AUTOSAR XML (schema 4-0-3)
package /Svc_NvM
  4 x impl type:
    NvM_BlockIdType: implementation-data-type=uint16
    NvM_RequestResultType: compu {0=NVM_REQ_OK, 1=NVM_REQ_NOT_OK, 2=NVM_REQ_PENDING, 3=NVM_REQ_INTEGRITY_FAILED, 4=NVM_REQ_BLOCK_SKIPPED, 5=NVM_REQ_NV_INVALIDATED, 6=NVM_REQ_CANCELED, 7=NVM_REQ_REDUNDANCY_FAILED, 8=NVM_REQ_RESTORED_FROM_ROM, 9=NVM_MAXVALUE}, implementation-data-type=uint8
    VoidPtr: category=DATA_REFERENCE, sw-pointer-target-props={target-category=VALUE, base-type=void}
    ConstVoidPtr: category=DATA_REFERENCE, sw-pointer-target-props={target-category=VALUE, base-type=void, sw-impl-policy=CONST}
  client server interface NvMNotifyInitBlock: is-service=true, service-kind=NON-VOLATILE-RAM-MANAGER
    operation InitBlock
  client server interface NvMNotifyJobFinished: is-service=true, service-kind=NON-VOLATILE-RAM-MANAGER
    operation JobFinished
      arg ServiceId: type=uint8, direction=IN
      arg JobResult: type=NvM_RequestResultType, direction=IN
  client server interface NvMService: is-service=true, service-kind=NON-VOLATILE-RAM-MANAGER
    8 x operation, all with possible-error=E_NOT_OK:
      GetErrorStatus
        arg RequestResultPtr: type=NvM_RequestResultType, direction=OUT
      SetRamBlockStatus
        arg BlockChanged: type=boolean, direction=IN
      ReadBlock
        arg Destination: type=VoidPtr, direction=IN
      WriteBlock
        arg Source: type=ConstVoidPtr, direction=IN
      RestoreBlockDefaults
        arg DstPtr: type=VoidPtr, direction=IN
      CancelJobs
      EraseNvBlock
      InvalidateNvBlock
    error E_NOT_OK: error-code=1
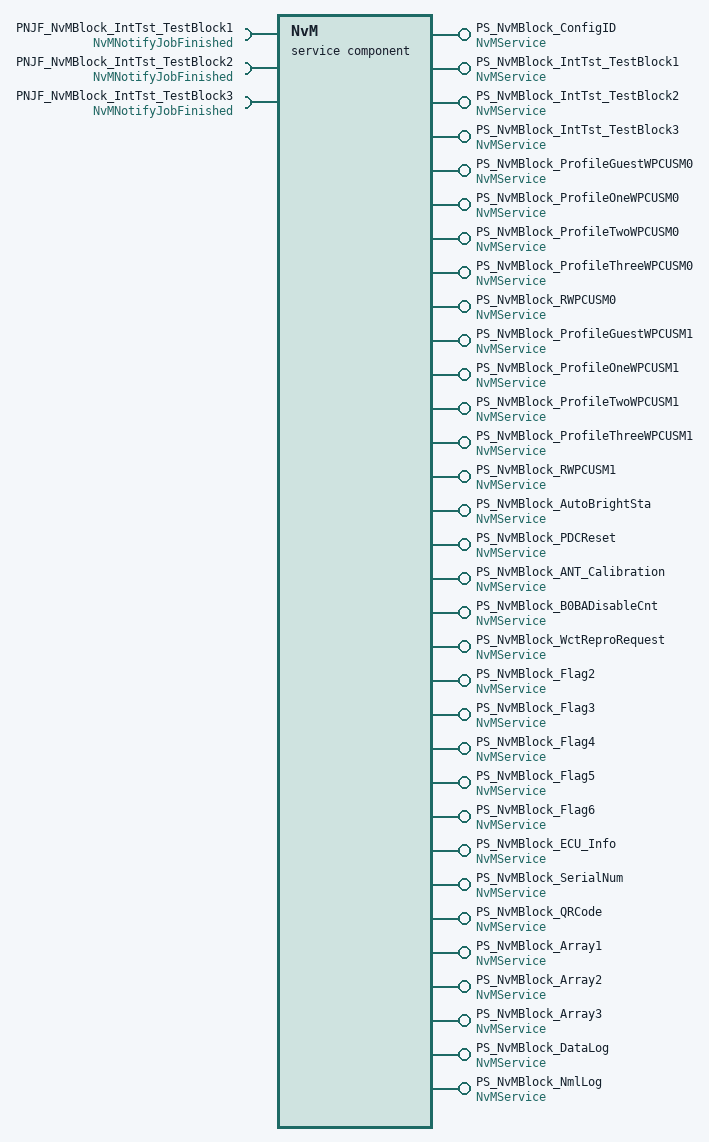
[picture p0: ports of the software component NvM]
  service sw component type NvM
    provide port PS_NvMBlock_ConfigID: provided-interface=NvMService
      provided-com-specs:
        operation=CancelJobs, queue-length=1
        operation=EraseNvBlock, queue-length=1
        operation=GetErrorStatus, queue-length=1
        operation=InvalidateNvBlock, queue-length=1
        operation=ReadBlock, queue-length=1
        operation=RestoreBlockDefaults, queue-length=1
        operation=SetRamBlockStatus, queue-length=1
        operation=WriteBlock, queue-length=1
    provide port PS_NvMBlock_IntTst_TestBlock1: provided-interface=NvMService
      provided-com-specs:
        operation=CancelJobs, queue-length=1
        operation=EraseNvBlock, queue-length=1
        operation=GetErrorStatus, queue-length=1
        operation=InvalidateNvBlock, queue-length=1
        operation=ReadBlock, queue-length=1
        operation=RestoreBlockDefaults, queue-length=1
        operation=SetRamBlockStatus, queue-length=1
        operation=WriteBlock, queue-length=1
    require port PNJF_NvMBlock_IntTst_TestBlock1: client-com-spec=JobFinished, required-interface=NvMNotifyJobFinished
    provide port PS_NvMBlock_IntTst_TestBlock2: provided-interface=NvMService
      provided-com-specs:
        operation=CancelJobs, queue-length=1
        operation=EraseNvBlock, queue-length=1
        operation=GetErrorStatus, queue-length=1
        operation=InvalidateNvBlock, queue-length=1
        operation=ReadBlock, queue-length=1
        operation=RestoreBlockDefaults, queue-length=1
        operation=SetRamBlockStatus, queue-length=1
        operation=WriteBlock, queue-length=1
    require port PNJF_NvMBlock_IntTst_TestBlock2: client-com-spec=JobFinished, required-interface=NvMNotifyJobFinished
    provide port PS_NvMBlock_IntTst_TestBlock3: provided-interface=NvMService
      provided-com-specs:
        operation=CancelJobs, queue-length=1
        operation=EraseNvBlock, queue-length=1
        operation=GetErrorStatus, queue-length=1
        operation=InvalidateNvBlock, queue-length=1
        operation=ReadBlock, queue-length=1
        operation=RestoreBlockDefaults, queue-length=1
        operation=SetRamBlockStatus, queue-length=1
        operation=WriteBlock, queue-length=1
    require port PNJF_NvMBlock_IntTst_TestBlock3: client-com-spec=JobFinished, required-interface=NvMNotifyJobFinished
    28 x provide port, all with provided-interface=NvMService:
      PS_NvMBlock_ProfileGuestWPCUSM0
        provided-com-specs:
          operation=CancelJobs, queue-length=1
          operation=EraseNvBlock, queue-length=1
          operation=GetErrorStatus, queue-length=1
          operation=InvalidateNvBlock, queue-length=1
          operation=ReadBlock, queue-length=1
          operation=RestoreBlockDefaults, queue-length=1
          operation=SetRamBlockStatus, queue-length=1
          operation=WriteBlock, queue-length=1
      PS_NvMBlock_ProfileOneWPCUSM0
        provided-com-specs:
          operation=CancelJobs, queue-length=1
          operation=EraseNvBlock, queue-length=1
          operation=GetErrorStatus, queue-length=1
          operation=InvalidateNvBlock, queue-length=1
          operation=ReadBlock, queue-length=1
          operation=RestoreBlockDefaults, queue-length=1
          operation=SetRamBlockStatus, queue-length=1
          operation=WriteBlock, queue-length=1
      PS_NvMBlock_ProfileTwoWPCUSM0
        provided-com-specs:
          operation=CancelJobs, queue-length=1
          operation=EraseNvBlock, queue-length=1
          operation=GetErrorStatus, queue-length=1
          operation=InvalidateNvBlock, queue-length=1
          operation=ReadBlock, queue-length=1
          operation=RestoreBlockDefaults, queue-length=1
          operation=SetRamBlockStatus, queue-length=1
          operation=WriteBlock, queue-length=1
      PS_NvMBlock_ProfileThreeWPCUSM0
        provided-com-specs:
          operation=CancelJobs, queue-length=1
          operation=EraseNvBlock, queue-length=1
          operation=GetErrorStatus, queue-length=1
          operation=InvalidateNvBlock, queue-length=1
          operation=ReadBlock, queue-length=1
          operation=RestoreBlockDefaults, queue-length=1
          operation=SetRamBlockStatus, queue-length=1
          operation=WriteBlock, queue-length=1
      PS_NvMBlock_RWPCUSM0
        provided-com-specs:
          operation=CancelJobs, queue-length=1
          operation=EraseNvBlock, queue-length=1
          operation=GetErrorStatus, queue-length=1
          operation=InvalidateNvBlock, queue-length=1
          operation=ReadBlock, queue-length=1
          operation=RestoreBlockDefaults, queue-length=1
          operation=SetRamBlockStatus, queue-length=1
          operation=WriteBlock, queue-length=1
      PS_NvMBlock_ProfileGuestWPCUSM1
        provided-com-specs:
          operation=CancelJobs, queue-length=1
          operation=EraseNvBlock, queue-length=1
          operation=GetErrorStatus, queue-length=1
          operation=InvalidateNvBlock, queue-length=1
          operation=ReadBlock, queue-length=1
          operation=RestoreBlockDefaults, queue-length=1
          operation=SetRamBlockStatus, queue-length=1
          operation=WriteBlock, queue-length=1
      PS_NvMBlock_ProfileOneWPCUSM1
        provided-com-specs:
          operation=CancelJobs, queue-length=1
          operation=EraseNvBlock, queue-length=1
          operation=GetErrorStatus, queue-length=1
          operation=InvalidateNvBlock, queue-length=1
          operation=ReadBlock, queue-length=1
          operation=RestoreBlockDefaults, queue-length=1
          operation=SetRamBlockStatus, queue-length=1
          operation=WriteBlock, queue-length=1
      PS_NvMBlock_ProfileTwoWPCUSM1
        provided-com-specs:
          operation=CancelJobs, queue-length=1
          operation=EraseNvBlock, queue-length=1
          operation=GetErrorStatus, queue-length=1
          operation=InvalidateNvBlock, queue-length=1
          operation=ReadBlock, queue-length=1
          operation=RestoreBlockDefaults, queue-length=1
          operation=SetRamBlockStatus, queue-length=1
          operation=WriteBlock, queue-length=1
      PS_NvMBlock_ProfileThreeWPCUSM1
        provided-com-specs:
          operation=CancelJobs, queue-length=1
          operation=EraseNvBlock, queue-length=1
          operation=GetErrorStatus, queue-length=1
          operation=InvalidateNvBlock, queue-length=1
          operation=ReadBlock, queue-length=1
          operation=RestoreBlockDefaults, queue-length=1
          operation=SetRamBlockStatus, queue-length=1
          operation=WriteBlock, queue-length=1
      PS_NvMBlock_RWPCUSM1
        provided-com-specs:
          operation=CancelJobs, queue-length=1
          operation=EraseNvBlock, queue-length=1
          operation=GetErrorStatus, queue-length=1
          operation=InvalidateNvBlock, queue-length=1
          operation=ReadBlock, queue-length=1
          operation=RestoreBlockDefaults, queue-length=1
          operation=SetRamBlockStatus, queue-length=1
          operation=WriteBlock, queue-length=1
      PS_NvMBlock_AutoBrightSta
        provided-com-specs:
          operation=CancelJobs, queue-length=1
          operation=EraseNvBlock, queue-length=1
          operation=GetErrorStatus, queue-length=1
          operation=InvalidateNvBlock, queue-length=1
          operation=ReadBlock, queue-length=1
          operation=RestoreBlockDefaults, queue-length=1
          operation=SetRamBlockStatus, queue-length=1
          operation=WriteBlock, queue-length=1
      PS_NvMBlock_PDCReset
        provided-com-specs:
          operation=CancelJobs, queue-length=1
          operation=EraseNvBlock, queue-length=1
          operation=GetErrorStatus, queue-length=1
          operation=InvalidateNvBlock, queue-length=1
          operation=ReadBlock, queue-length=1
          operation=RestoreBlockDefaults, queue-length=1
          operation=SetRamBlockStatus, queue-length=1
          operation=WriteBlock, queue-length=1
      PS_NvMBlock_ANT_Calibration
        provided-com-specs:
          operation=CancelJobs, queue-length=1
          operation=EraseNvBlock, queue-length=1
          operation=GetErrorStatus, queue-length=1
          operation=InvalidateNvBlock, queue-length=1
          operation=ReadBlock, queue-length=1
          operation=RestoreBlockDefaults, queue-length=1
          operation=SetRamBlockStatus, queue-length=1
          operation=WriteBlock, queue-length=1
      PS_NvMBlock_B0BADisableCnt
        provided-com-specs:
          operation=CancelJobs, queue-length=1
          operation=EraseNvBlock, queue-length=1
          operation=GetErrorStatus, queue-length=1
          operation=InvalidateNvBlock, queue-length=1
          operation=ReadBlock, queue-length=1
          operation=RestoreBlockDefaults, queue-length=1
          operation=SetRamBlockStatus, queue-length=1
          operation=WriteBlock, queue-length=1
      PS_NvMBlock_WctReproRequest
        provided-com-specs:
          operation=CancelJobs, queue-length=1
          operation=EraseNvBlock, queue-length=1
          operation=GetErrorStatus, queue-length=1
          operation=InvalidateNvBlock, queue-length=1
          operation=ReadBlock, queue-length=1
          operation=RestoreBlockDefaults, queue-length=1
          operation=SetRamBlockStatus, queue-length=1
          operation=WriteBlock, queue-length=1
      PS_NvMBlock_Flag2
        provided-com-specs:
          operation=CancelJobs, queue-length=1
          operation=EraseNvBlock, queue-length=1
          operation=GetErrorStatus, queue-length=1
          operation=InvalidateNvBlock, queue-length=1
          operation=ReadBlock, queue-length=1
          operation=RestoreBlockDefaults, queue-length=1
          operation=SetRamBlockStatus, queue-length=1
          operation=WriteBlock, queue-length=1
      PS_NvMBlock_Flag3
        provided-com-specs:
          operation=CancelJobs, queue-length=1
          operation=EraseNvBlock, queue-length=1
          operation=GetErrorStatus, queue-length=1
          operation=InvalidateNvBlock, queue-length=1
          operation=ReadBlock, queue-length=1
          operation=RestoreBlockDefaults, queue-length=1
          operation=SetRamBlockStatus, queue-length=1
          operation=WriteBlock, queue-length=1
      PS_NvMBlock_Flag4
        provided-com-specs:
          operation=CancelJobs, queue-length=1
          operation=EraseNvBlock, queue-length=1
          operation=GetErrorStatus, queue-length=1
          operation=InvalidateNvBlock, queue-length=1
          operation=ReadBlock, queue-length=1
          operation=RestoreBlockDefaults, queue-length=1
          operation=SetRamBlockStatus, queue-length=1
          operation=WriteBlock, queue-length=1
      PS_NvMBlock_Flag5
        provided-com-specs:
          operation=CancelJobs, queue-length=1
          operation=EraseNvBlock, queue-length=1
          operation=GetErrorStatus, queue-length=1
          operation=InvalidateNvBlock, queue-length=1
          operation=ReadBlock, queue-length=1
          operation=RestoreBlockDefaults, queue-length=1
          operation=SetRamBlockStatus, queue-length=1
          operation=WriteBlock, queue-length=1
      PS_NvMBlock_Flag6
        provided-com-specs:
          operation=CancelJobs, queue-length=1
          operation=EraseNvBlock, queue-length=1
          operation=GetErrorStatus, queue-length=1
          operation=InvalidateNvBlock, queue-length=1
          operation=ReadBlock, queue-length=1
          operation=RestoreBlockDefaults, queue-length=1
          operation=SetRamBlockStatus, queue-length=1
          operation=WriteBlock, queue-length=1
      PS_NvMBlock_ECU_Info
        provided-com-specs:
          operation=CancelJobs, queue-length=1
          operation=EraseNvBlock, queue-length=1
          operation=GetErrorStatus, queue-length=1
          operation=InvalidateNvBlock, queue-length=1
          operation=ReadBlock, queue-length=1
          operation=RestoreBlockDefaults, queue-length=1
          operation=SetRamBlockStatus, queue-length=1
          operation=WriteBlock, queue-length=1
      PS_NvMBlock_SerialNum
        provided-com-specs:
          operation=CancelJobs, queue-length=1
          operation=EraseNvBlock, queue-length=1
          operation=GetErrorStatus, queue-length=1
          operation=InvalidateNvBlock, queue-length=1
          operation=ReadBlock, queue-length=1
          operation=RestoreBlockDefaults, queue-length=1
          operation=SetRamBlockStatus, queue-length=1
          operation=WriteBlock, queue-length=1
      PS_NvMBlock_QRCode
        provided-com-specs:
          operation=CancelJobs, queue-length=1
          operation=EraseNvBlock, queue-length=1
          operation=GetErrorStatus, queue-length=1
          operation=InvalidateNvBlock, queue-length=1
          operation=ReadBlock, queue-length=1
          operation=RestoreBlockDefaults, queue-length=1
          operation=SetRamBlockStatus, queue-length=1
          operation=WriteBlock, queue-length=1
      PS_NvMBlock_Array1
        provided-com-specs:
          operation=CancelJobs, queue-length=1
          operation=EraseNvBlock, queue-length=1
          operation=GetErrorStatus, queue-length=1
          operation=InvalidateNvBlock, queue-length=1
          operation=ReadBlock, queue-length=1
          operation=RestoreBlockDefaults, queue-length=1
          operation=SetRamBlockStatus, queue-length=1
          operation=WriteBlock, queue-length=1
      PS_NvMBlock_Array2
        provided-com-specs:
          operation=CancelJobs, queue-length=1
          operation=EraseNvBlock, queue-length=1
          operation=GetErrorStatus, queue-length=1
          operation=InvalidateNvBlock, queue-length=1
          operation=ReadBlock, queue-length=1
          operation=RestoreBlockDefaults, queue-length=1
          operation=SetRamBlockStatus, queue-length=1
          operation=WriteBlock, queue-length=1
      PS_NvMBlock_Array3
        provided-com-specs:
          operation=CancelJobs, queue-length=1
          operation=EraseNvBlock, queue-length=1
          operation=GetErrorStatus, queue-length=1
          operation=InvalidateNvBlock, queue-length=1
          operation=ReadBlock, queue-length=1
          operation=RestoreBlockDefaults, queue-length=1
          operation=SetRamBlockStatus, queue-length=1
          operation=WriteBlock, queue-length=1
      PS_NvMBlock_DataLog
        provided-com-specs:
          operation=CancelJobs, queue-length=1
          operation=EraseNvBlock, queue-length=1
          operation=GetErrorStatus, queue-length=1
          operation=InvalidateNvBlock, queue-length=1
          operation=ReadBlock, queue-length=1
          operation=RestoreBlockDefaults, queue-length=1
          operation=SetRamBlockStatus, queue-length=1
          operation=WriteBlock, queue-length=1
      PS_NvMBlock_NmlLog
        provided-com-specs:
          operation=CancelJobs, queue-length=1
          operation=EraseNvBlock, queue-length=1
          operation=GetErrorStatus, queue-length=1
          operation=InvalidateNvBlock, queue-length=1
          operation=ReadBlock, queue-length=1
          operation=RestoreBlockDefaults, queue-length=1
          operation=SetRamBlockStatus, queue-length=1
          operation=WriteBlock, queue-length=1
    behavior IB_NvM: handle-termination-and-restart=NO-SUPPORT
      256 x operation invoked event:
        OperationInvokedEvent_PS_NvMBlock_ConfigID_CancelJobs: start-on-event=CancelJobs, operation=PS_NvMBlock_ConfigID.CancelJobs
        OperationInvokedEvent_PS_NvMBlock_ConfigID_EraseNvBlock: start-on-event=EraseNvBlock, operation=PS_NvMBlock_ConfigID.EraseNvBlock
        OperationInvokedEvent_PS_NvMBlock_ConfigID_GetErrorStatus: start-on-event=GetErrorStatus, operation=PS_NvMBlock_ConfigID.GetErrorStatus
        OperationInvokedEvent_PS_NvMBlock_ConfigID_InvalidateNvBlock: start-on-event=InvalidateNvBlock, operation=PS_NvMBlock_ConfigID.InvalidateNvBlock
        OperationInvokedEvent_PS_NvMBlock_ConfigID_ReadBlock: start-on-event=ReadBlock, operation=PS_NvMBlock_ConfigID.ReadBlock
        OperationInvokedEvent_PS_NvMBlock_ConfigID_RestoreBlockDefaults: start-on-event=RestoreBlockDefaults, operation=PS_NvMBlock_ConfigID.RestoreBlockDefaults
        OperationInvokedEvent_PS_NvMBlock_ConfigID_SetRamBlockStatus: start-on-event=SetRamBlockStatus, operation=PS_NvMBlock_ConfigID.SetRamBlockStatus
        OperationInvokedEvent_PS_NvMBlock_ConfigID_WriteBlock: start-on-event=WriteBlock, operation=PS_NvMBlock_ConfigID.WriteBlock
        OperationInvokedEvent_PS_NvMBlock_IntTst_TestBlock1_CancelJobs: start-on-event=CancelJobs, operation=PS_NvMBlock_IntTst_TestBlock1.CancelJobs
        OperationInvokedEvent_PS_NvMBlock_IntTst_TestBlock1_EraseNvBlock: start-on-event=EraseNvBlock, operation=PS_NvMBlock_IntTst_TestBlock1.EraseNvBlock
        OperationInvokedEvent_PS_NvMBlock_IntTst_TestBlock1_GetErrorStatus: start-on-event=GetErrorStatus, operation=PS_NvMBlock_IntTst_TestBlock1.GetErrorStatus
        OperationInvokedEvent_PS_NvMBlock_IntTst_TestBlock1_InvalidateNvBlock: start-on-event=InvalidateNvBlock, operation=PS_NvMBlock_IntTst_TestBlock1.InvalidateNvBlock
        OperationInvokedEvent_PS_NvMBlock_IntTst_TestBlock1_ReadBlock: start-on-event=ReadBlock, operation=PS_NvMBlock_IntTst_TestBlock1.ReadBlock
        OperationInvokedEvent_PS_NvMBlock_IntTst_TestBlock1_RestoreBlockDefaults: start-on-event=RestoreBlockDefaults, operation=PS_NvMBlock_IntTst_TestBlock1.RestoreBlockDefaults
        OperationInvokedEvent_PS_NvMBlock_IntTst_TestBlock1_SetRamBlockStatus: start-on-event=SetRamBlockStatus, operation=PS_NvMBlock_IntTst_TestBlock1.SetRamBlockStatus
        OperationInvokedEvent_PS_NvMBlock_IntTst_TestBlock1_WriteBlock: start-on-event=WriteBlock, operation=PS_NvMBlock_IntTst_TestBlock1.WriteBlock
        OperationInvokedEvent_PS_NvMBlock_IntTst_TestBlock2_CancelJobs: start-on-event=CancelJobs, operation=PS_NvMBlock_IntTst_TestBlock2.CancelJobs
        OperationInvokedEvent_PS_NvMBlock_IntTst_TestBlock2_EraseNvBlock: start-on-event=EraseNvBlock, operation=PS_NvMBlock_IntTst_TestBlock2.EraseNvBlock
        OperationInvokedEvent_PS_NvMBlock_IntTst_TestBlock2_GetErrorStatus: start-on-event=GetErrorStatus, operation=PS_NvMBlock_IntTst_TestBlock2.GetErrorStatus
        OperationInvokedEvent_PS_NvMBlock_IntTst_TestBlock2_InvalidateNvBlock: start-on-event=InvalidateNvBlock, operation=PS_NvMBlock_IntTst_TestBlock2.InvalidateNvBlock
        OperationInvokedEvent_PS_NvMBlock_IntTst_TestBlock2_ReadBlock: start-on-event=ReadBlock, operation=PS_NvMBlock_IntTst_TestBlock2.ReadBlock
        OperationInvokedEvent_PS_NvMBlock_IntTst_TestBlock2_RestoreBlockDefaults: start-on-event=RestoreBlockDefaults, operation=PS_NvMBlock_IntTst_TestBlock2.RestoreBlockDefaults
        OperationInvokedEvent_PS_NvMBlock_IntTst_TestBlock2_SetRamBlockStatus: start-on-event=SetRamBlockStatus, operation=PS_NvMBlock_IntTst_TestBlock2.SetRamBlockStatus
        OperationInvokedEvent_PS_NvMBlock_IntTst_TestBlock2_WriteBlock: start-on-event=WriteBlock, operation=PS_NvMBlock_IntTst_TestBlock2.WriteBlock
        OperationInvokedEvent_PS_NvMBlock_IntTst_TestBlock3_CancelJobs: start-on-event=CancelJobs, operation=PS_NvMBlock_IntTst_TestBlock3.CancelJobs
        OperationInvokedEvent_PS_NvMBlock_IntTst_TestBlock3_EraseNvBlock: start-on-event=EraseNvBlock, operation=PS_NvMBlock_IntTst_TestBlock3.EraseNvBlock
        OperationInvokedEvent_PS_NvMBlock_IntTst_TestBlock3_GetErrorStatus: start-on-event=GetErrorStatus, operation=PS_NvMBlock_IntTst_TestBlock3.GetErrorStatus
        OperationInvokedEvent_PS_NvMBlock_IntTst_TestBlock3_InvalidateNvBlock: start-on-event=InvalidateNvBlock, operation=PS_NvMBlock_IntTst_TestBlock3.InvalidateNvBlock
        OperationInvokedEvent_PS_NvMBlock_IntTst_TestBlock3_ReadBlock: start-on-event=ReadBlock, operation=PS_NvMBlock_IntTst_TestBlock3.ReadBlock
        OperationInvokedEvent_PS_NvMBlock_IntTst_TestBlock3_RestoreBlockDefaults: start-on-event=RestoreBlockDefaults, operation=PS_NvMBlock_IntTst_TestBlock3.RestoreBlockDefaults
        OperationInvokedEvent_PS_NvMBlock_IntTst_TestBlock3_SetRamBlockStatus: start-on-event=SetRamBlockStatus, operation=PS_NvMBlock_IntTst_TestBlock3.SetRamBlockStatus
        OperationInvokedEvent_PS_NvMBlock_IntTst_TestBlock3_WriteBlock: start-on-event=WriteBlock, operation=PS_NvMBlock_IntTst_TestBlock3.WriteBlock
        OperationInvokedEvent_PS_NvMBlock_ProfileGuestWPCUSM0_CancelJobs: start-on-event=CancelJobs, operation=PS_NvMBlock_ProfileGuestWPCUSM0.CancelJobs
        OperationInvokedEvent_PS_NvMBlock_ProfileGuestWPCUSM0_EraseNvBlock: start-on-event=EraseNvBlock, operation=PS_NvMBlock_ProfileGuestWPCUSM0.EraseNvBlock
        OperationInvokedEvent_PS_NvMBlock_ProfileGuestWPCUSM0_GetErrorStatus: start-on-event=GetErrorStatus, operation=PS_NvMBlock_ProfileGuestWPCUSM0.GetErrorStatus
        OperationInvokedEvent_PS_NvMBlock_ProfileGuestWPCUSM0_InvalidateNvBlock: start-on-event=InvalidateNvBlock, operation=PS_NvMBlock_ProfileGuestWPCUSM0.InvalidateNvBlock
        OperationInvokedEvent_PS_NvMBlock_ProfileGuestWPCUSM0_ReadBlock: start-on-event=ReadBlock, operation=PS_NvMBlock_ProfileGuestWPCUSM0.ReadBlock
        OperationInvokedEvent_PS_NvMBlock_ProfileGuestWPCUSM0_RestoreBlockDefaults: start-on-event=RestoreBlockDefaults, operation=PS_NvMBlock_ProfileGuestWPCUSM0.RestoreBlockDefaults
        OperationInvokedEvent_PS_NvMBlock_ProfileGuestWPCUSM0_SetRamBlockStatus: start-on-event=SetRamBlockStatus, operation=PS_NvMBlock_ProfileGuestWPCUSM0.SetRamBlockStatus
        OperationInvokedEvent_PS_NvMBlock_ProfileGuestWPCUSM0_WriteBlock: start-on-event=WriteBlock, operation=PS_NvMBlock_ProfileGuestWPCUSM0.WriteBlock
        OperationInvokedEvent_PS_NvMBlock_ProfileOneWPCUSM0_CancelJobs: start-on-event=CancelJobs, operation=PS_NvMBlock_ProfileOneWPCUSM0.CancelJobs
        OperationInvokedEvent_PS_NvMBlock_ProfileOneWPCUSM0_EraseNvBlock: start-on-event=EraseNvBlock, operation=PS_NvMBlock_ProfileOneWPCUSM0.EraseNvBlock
        OperationInvokedEvent_PS_NvMBlock_ProfileOneWPCUSM0_GetErrorStatus: start-on-event=GetErrorStatus, operation=PS_NvMBlock_ProfileOneWPCUSM0.GetErrorStatus
        OperationInvokedEvent_PS_NvMBlock_ProfileOneWPCUSM0_InvalidateNvBlock: start-on-event=InvalidateNvBlock, operation=PS_NvMBlock_ProfileOneWPCUSM0.InvalidateNvBlock
        OperationInvokedEvent_PS_NvMBlock_ProfileOneWPCUSM0_ReadBlock: start-on-event=ReadBlock, operation=PS_NvMBlock_ProfileOneWPCUSM0.ReadBlock
        OperationInvokedEvent_PS_NvMBlock_ProfileOneWPCUSM0_RestoreBlockDefaults: start-on-event=RestoreBlockDefaults, operation=PS_NvMBlock_ProfileOneWPCUSM0.RestoreBlockDefaults
        OperationInvokedEvent_PS_NvMBlock_ProfileOneWPCUSM0_SetRamBlockStatus: start-on-event=SetRamBlockStatus, operation=PS_NvMBlock_ProfileOneWPCUSM0.SetRamBlockStatus
        OperationInvokedEvent_PS_NvMBlock_ProfileOneWPCUSM0_WriteBlock: start-on-event=WriteBlock, operation=PS_NvMBlock_ProfileOneWPCUSM0.WriteBlock
        OperationInvokedEvent_PS_NvMBlock_ProfileTwoWPCUSM0_CancelJobs: start-on-event=CancelJobs, operation=PS_NvMBlock_ProfileTwoWPCUSM0.CancelJobs
        OperationInvokedEvent_PS_NvMBlock_ProfileTwoWPCUSM0_EraseNvBlock: start-on-event=EraseNvBlock, operation=PS_NvMBlock_ProfileTwoWPCUSM0.EraseNvBlock
        OperationInvokedEvent_PS_NvMBlock_ProfileTwoWPCUSM0_GetErrorStatus: start-on-event=GetErrorStatus, operation=PS_NvMBlock_ProfileTwoWPCUSM0.GetErrorStatus
        OperationInvokedEvent_PS_NvMBlock_ProfileTwoWPCUSM0_InvalidateNvBlock: start-on-event=InvalidateNvBlock, operation=PS_NvMBlock_ProfileTwoWPCUSM0.InvalidateNvBlock
        OperationInvokedEvent_PS_NvMBlock_ProfileTwoWPCUSM0_ReadBlock: start-on-event=ReadBlock, operation=PS_NvMBlock_ProfileTwoWPCUSM0.ReadBlock
        OperationInvokedEvent_PS_NvMBlock_ProfileTwoWPCUSM0_RestoreBlockDefaults: start-on-event=RestoreBlockDefaults, operation=PS_NvMBlock_ProfileTwoWPCUSM0.RestoreBlockDefaults
        OperationInvokedEvent_PS_NvMBlock_ProfileTwoWPCUSM0_SetRamBlockStatus: start-on-event=SetRamBlockStatus, operation=PS_NvMBlock_ProfileTwoWPCUSM0.SetRamBlockStatus
        OperationInvokedEvent_PS_NvMBlock_ProfileTwoWPCUSM0_WriteBlock: start-on-event=WriteBlock, operation=PS_NvMBlock_ProfileTwoWPCUSM0.WriteBlock
        OperationInvokedEvent_PS_NvMBlock_ProfileThreeWPCUSM0_CancelJobs: start-on-event=CancelJobs, operation=PS_NvMBlock_ProfileThreeWPCUSM0.CancelJobs
        OperationInvokedEvent_PS_NvMBlock_ProfileThreeWPCUSM0_EraseNvBlock: start-on-event=EraseNvBlock, operation=PS_NvMBlock_ProfileThreeWPCUSM0.EraseNvBlock
        OperationInvokedEvent_PS_NvMBlock_ProfileThreeWPCUSM0_GetErrorStatus: start-on-event=GetErrorStatus, operation=PS_NvMBlock_ProfileThreeWPCUSM0.GetErrorStatus
        OperationInvokedEvent_PS_NvMBlock_ProfileThreeWPCUSM0_InvalidateNvBlock: start-on-event=InvalidateNvBlock, operation=PS_NvMBlock_ProfileThreeWPCUSM0.InvalidateNvBlock
        OperationInvokedEvent_PS_NvMBlock_ProfileThreeWPCUSM0_ReadBlock: start-on-event=ReadBlock, operation=PS_NvMBlock_ProfileThreeWPCUSM0.ReadBlock
        OperationInvokedEvent_PS_NvMBlock_ProfileThreeWPCUSM0_RestoreBlockDefaults: start-on-event=RestoreBlockDefaults, operation=PS_NvMBlock_ProfileThreeWPCUSM0.RestoreBlockDefaults
        OperationInvokedEvent_PS_NvMBlock_ProfileThreeWPCUSM0_SetRamBlockStatus: start-on-event=SetRamBlockStatus, operation=PS_NvMBlock_ProfileThreeWPCUSM0.SetRamBlockStatus
        OperationInvokedEvent_PS_NvMBlock_ProfileThreeWPCUSM0_WriteBlock: start-on-event=WriteBlock, operation=PS_NvMBlock_ProfileThreeWPCUSM0.WriteBlock
        OperationInvokedEvent_PS_NvMBlock_RWPCUSM0_CancelJobs: start-on-event=CancelJobs, operation=PS_NvMBlock_RWPCUSM0.CancelJobs
        OperationInvokedEvent_PS_NvMBlock_RWPCUSM0_EraseNvBlock: start-on-event=EraseNvBlock, operation=PS_NvMBlock_RWPCUSM0.EraseNvBlock
        OperationInvokedEvent_PS_NvMBlock_RWPCUSM0_GetErrorStatus: start-on-event=GetErrorStatus, operation=PS_NvMBlock_RWPCUSM0.GetErrorStatus
        OperationInvokedEvent_PS_NvMBlock_RWPCUSM0_InvalidateNvBlock: start-on-event=InvalidateNvBlock, operation=PS_NvMBlock_RWPCUSM0.InvalidateNvBlock
        OperationInvokedEvent_PS_NvMBlock_RWPCUSM0_ReadBlock: start-on-event=ReadBlock, operation=PS_NvMBlock_RWPCUSM0.ReadBlock
        OperationInvokedEvent_PS_NvMBlock_RWPCUSM0_RestoreBlockDefaults: start-on-event=RestoreBlockDefaults, operation=PS_NvMBlock_RWPCUSM0.RestoreBlockDefaults
        OperationInvokedEvent_PS_NvMBlock_RWPCUSM0_SetRamBlockStatus: start-on-event=SetRamBlockStatus, operation=PS_NvMBlock_RWPCUSM0.SetRamBlockStatus
        OperationInvokedEvent_PS_NvMBlock_RWPCUSM0_WriteBlock: start-on-event=WriteBlock, operation=PS_NvMBlock_RWPCUSM0.WriteBlock
        OperationInvokedEvent_PS_NvMBlock_ProfileGuestWPCUSM1_CancelJobs: start-on-event=CancelJobs, operation=PS_NvMBlock_ProfileGuestWPCUSM1.CancelJobs
        OperationInvokedEvent_PS_NvMBlock_ProfileGuestWPCUSM1_EraseNvBlock: start-on-event=EraseNvBlock, operation=PS_NvMBlock_ProfileGuestWPCUSM1.EraseNvBlock
        OperationInvokedEvent_PS_NvMBlock_ProfileGuestWPCUSM1_GetErrorStatus: start-on-event=GetErrorStatus, operation=PS_NvMBlock_ProfileGuestWPCUSM1.GetErrorStatus
        OperationInvokedEvent_PS_NvMBlock_ProfileGuestWPCUSM1_InvalidateNvBlock: start-on-event=InvalidateNvBlock, operation=PS_NvMBlock_ProfileGuestWPCUSM1.InvalidateNvBlock
        OperationInvokedEvent_PS_NvMBlock_ProfileGuestWPCUSM1_ReadBlock: start-on-event=ReadBlock, operation=PS_NvMBlock_ProfileGuestWPCUSM1.ReadBlock
        OperationInvokedEvent_PS_NvMBlock_ProfileGuestWPCUSM1_RestoreBlockDefaults: start-on-event=RestoreBlockDefaults, operation=PS_NvMBlock_ProfileGuestWPCUSM1.RestoreBlockDefaults
        OperationInvokedEvent_PS_NvMBlock_ProfileGuestWPCUSM1_SetRamBlockStatus: start-on-event=SetRamBlockStatus, operation=PS_NvMBlock_ProfileGuestWPCUSM1.SetRamBlockStatus
        OperationInvokedEvent_PS_NvMBlock_ProfileGuestWPCUSM1_WriteBlock: start-on-event=WriteBlock, operation=PS_NvMBlock_ProfileGuestWPCUSM1.WriteBlock
        OperationInvokedEvent_PS_NvMBlock_ProfileOneWPCUSM1_CancelJobs: start-on-event=CancelJobs, operation=PS_NvMBlock_ProfileOneWPCUSM1.CancelJobs
        OperationInvokedEvent_PS_NvMBlock_ProfileOneWPCUSM1_EraseNvBlock: start-on-event=EraseNvBlock, operation=PS_NvMBlock_ProfileOneWPCUSM1.EraseNvBlock
        OperationInvokedEvent_PS_NvMBlock_ProfileOneWPCUSM1_GetErrorStatus: start-on-event=GetErrorStatus, operation=PS_NvMBlock_ProfileOneWPCUSM1.GetErrorStatus
        OperationInvokedEvent_PS_NvMBlock_ProfileOneWPCUSM1_InvalidateNvBlock: start-on-event=InvalidateNvBlock, operation=PS_NvMBlock_ProfileOneWPCUSM1.InvalidateNvBlock
        OperationInvokedEvent_PS_NvMBlock_ProfileOneWPCUSM1_ReadBlock: start-on-event=ReadBlock, operation=PS_NvMBlock_ProfileOneWPCUSM1.ReadBlock
        OperationInvokedEvent_PS_NvMBlock_ProfileOneWPCUSM1_RestoreBlockDefaults: start-on-event=RestoreBlockDefaults, operation=PS_NvMBlock_ProfileOneWPCUSM1.RestoreBlockDefaults
        OperationInvokedEvent_PS_NvMBlock_ProfileOneWPCUSM1_SetRamBlockStatus: start-on-event=SetRamBlockStatus, operation=PS_NvMBlock_ProfileOneWPCUSM1.SetRamBlockStatus
        OperationInvokedEvent_PS_NvMBlock_ProfileOneWPCUSM1_WriteBlock: start-on-event=WriteBlock, operation=PS_NvMBlock_ProfileOneWPCUSM1.WriteBlock
        OperationInvokedEvent_PS_NvMBlock_ProfileTwoWPCUSM1_CancelJobs: start-on-event=CancelJobs, operation=PS_NvMBlock_ProfileTwoWPCUSM1.CancelJobs
        OperationInvokedEvent_PS_NvMBlock_ProfileTwoWPCUSM1_EraseNvBlock: start-on-event=EraseNvBlock, operation=PS_NvMBlock_ProfileTwoWPCUSM1.EraseNvBlock
        OperationInvokedEvent_PS_NvMBlock_ProfileTwoWPCUSM1_GetErrorStatus: start-on-event=GetErrorStatus, operation=PS_NvMBlock_ProfileTwoWPCUSM1.GetErrorStatus
        OperationInvokedEvent_PS_NvMBlock_ProfileTwoWPCUSM1_InvalidateNvBlock: start-on-event=InvalidateNvBlock, operation=PS_NvMBlock_ProfileTwoWPCUSM1.InvalidateNvBlock
        OperationInvokedEvent_PS_NvMBlock_ProfileTwoWPCUSM1_ReadBlock: start-on-event=ReadBlock, operation=PS_NvMBlock_ProfileTwoWPCUSM1.ReadBlock
        OperationInvokedEvent_PS_NvMBlock_ProfileTwoWPCUSM1_RestoreBlockDefaults: start-on-event=RestoreBlockDefaults, operation=PS_NvMBlock_ProfileTwoWPCUSM1.RestoreBlockDefaults
        OperationInvokedEvent_PS_NvMBlock_ProfileTwoWPCUSM1_SetRamBlockStatus: start-on-event=SetRamBlockStatus, operation=PS_NvMBlock_ProfileTwoWPCUSM1.SetRamBlockStatus
        OperationInvokedEvent_PS_NvMBlock_ProfileTwoWPCUSM1_WriteBlock: start-on-event=WriteBlock, operation=PS_NvMBlock_ProfileTwoWPCUSM1.WriteBlock
        OperationInvokedEvent_PS_NvMBlock_ProfileThreeWPCUSM1_CancelJobs: start-on-event=CancelJobs, operation=PS_NvMBlock_ProfileThreeWPCUSM1.CancelJobs
        OperationInvokedEvent_PS_NvMBlock_ProfileThreeWPCUSM1_EraseNvBlock: start-on-event=EraseNvBlock, operation=PS_NvMBlock_ProfileThreeWPCUSM1.EraseNvBlock
        OperationInvokedEvent_PS_NvMBlock_ProfileThreeWPCUSM1_GetErrorStatus: start-on-event=GetErrorStatus, operation=PS_NvMBlock_ProfileThreeWPCUSM1.GetErrorStatus
        OperationInvokedEvent_PS_NvMBlock_ProfileThreeWPCUSM1_InvalidateNvBlock: start-on-event=InvalidateNvBlock, operation=PS_NvMBlock_ProfileThreeWPCUSM1.InvalidateNvBlock
        OperationInvokedEvent_PS_NvMBlock_ProfileThreeWPCUSM1_ReadBlock: start-on-event=ReadBlock, operation=PS_NvMBlock_ProfileThreeWPCUSM1.ReadBlock
        OperationInvokedEvent_PS_NvMBlock_ProfileThreeWPCUSM1_RestoreBlockDefaults: start-on-event=RestoreBlockDefaults, operation=PS_NvMBlock_ProfileThreeWPCUSM1.RestoreBlockDefaults
        OperationInvokedEvent_PS_NvMBlock_ProfileThreeWPCUSM1_SetRamBlockStatus: start-on-event=SetRamBlockStatus, operation=PS_NvMBlock_ProfileThreeWPCUSM1.SetRamBlockStatus
        OperationInvokedEvent_PS_NvMBlock_ProfileThreeWPCUSM1_WriteBlock: start-on-event=WriteBlock, operation=PS_NvMBlock_ProfileThreeWPCUSM1.WriteBlock
        OperationInvokedEvent_PS_NvMBlock_RWPCUSM1_CancelJobs: start-on-event=CancelJobs, operation=PS_NvMBlock_RWPCUSM1.CancelJobs
        OperationInvokedEvent_PS_NvMBlock_RWPCUSM1_EraseNvBlock: start-on-event=EraseNvBlock, operation=PS_NvMBlock_RWPCUSM1.EraseNvBlock
        OperationInvokedEvent_PS_NvMBlock_RWPCUSM1_GetErrorStatus: start-on-event=GetErrorStatus, operation=PS_NvMBlock_RWPCUSM1.GetErrorStatus
        OperationInvokedEvent_PS_NvMBlock_RWPCUSM1_InvalidateNvBlock: start-on-event=InvalidateNvBlock, operation=PS_NvMBlock_RWPCUSM1.InvalidateNvBlock
        OperationInvokedEvent_PS_NvMBlock_RWPCUSM1_ReadBlock: start-on-event=ReadBlock, operation=PS_NvMBlock_RWPCUSM1.ReadBlock
        OperationInvokedEvent_PS_NvMBlock_RWPCUSM1_RestoreBlockDefaults: start-on-event=RestoreBlockDefaults, operation=PS_NvMBlock_RWPCUSM1.RestoreBlockDefaults
        OperationInvokedEvent_PS_NvMBlock_RWPCUSM1_SetRamBlockStatus: start-on-event=SetRamBlockStatus, operation=PS_NvMBlock_RWPCUSM1.SetRamBlockStatus
        OperationInvokedEvent_PS_NvMBlock_RWPCUSM1_WriteBlock: start-on-event=WriteBlock, operation=PS_NvMBlock_RWPCUSM1.WriteBlock
        OperationInvokedEvent_PS_NvMBlock_AutoBrightSta_CancelJobs: start-on-event=CancelJobs, operation=PS_NvMBlock_AutoBrightSta.CancelJobs
        OperationInvokedEvent_PS_NvMBlock_AutoBrightSta_EraseNvBlock: start-on-event=EraseNvBlock, operation=PS_NvMBlock_AutoBrightSta.EraseNvBlock
        OperationInvokedEvent_PS_NvMBlock_AutoBrightSta_GetErrorStatus: start-on-event=GetErrorStatus, operation=PS_NvMBlock_AutoBrightSta.GetErrorStatus
        OperationInvokedEvent_PS_NvMBlock_AutoBrightSta_InvalidateNvBlock: start-on-event=InvalidateNvBlock, operation=PS_NvMBlock_AutoBrightSta.InvalidateNvBlock
        OperationInvokedEvent_PS_NvMBlock_AutoBrightSta_ReadBlock: start-on-event=ReadBlock, operation=PS_NvMBlock_AutoBrightSta.ReadBlock
        OperationInvokedEvent_PS_NvMBlock_AutoBrightSta_RestoreBlockDefaults: start-on-event=RestoreBlockDefaults, operation=PS_NvMBlock_AutoBrightSta.RestoreBlockDefaults
        OperationInvokedEvent_PS_NvMBlock_AutoBrightSta_SetRamBlockStatus: start-on-event=SetRamBlockStatus, operation=PS_NvMBlock_AutoBrightSta.SetRamBlockStatus
        OperationInvokedEvent_PS_NvMBlock_AutoBrightSta_WriteBlock: start-on-event=WriteBlock, operation=PS_NvMBlock_AutoBrightSta.WriteBlock
        OperationInvokedEvent_PS_NvMBlock_PDCReset_CancelJobs: start-on-event=CancelJobs, operation=PS_NvMBlock_PDCReset.CancelJobs
        OperationInvokedEvent_PS_NvMBlock_PDCReset_EraseNvBlock: start-on-event=EraseNvBlock, operation=PS_NvMBlock_PDCReset.EraseNvBlock
        OperationInvokedEvent_PS_NvMBlock_PDCReset_GetErrorStatus: start-on-event=GetErrorStatus, operation=PS_NvMBlock_PDCReset.GetErrorStatus
        OperationInvokedEvent_PS_NvMBlock_PDCReset_InvalidateNvBlock: start-on-event=InvalidateNvBlock, operation=PS_NvMBlock_PDCReset.InvalidateNvBlock
        OperationInvokedEvent_PS_NvMBlock_PDCReset_ReadBlock: start-on-event=ReadBlock, operation=PS_NvMBlock_PDCReset.ReadBlock
        OperationInvokedEvent_PS_NvMBlock_PDCReset_RestoreBlockDefaults: start-on-event=RestoreBlockDefaults, operation=PS_NvMBlock_PDCReset.RestoreBlockDefaults
        OperationInvokedEvent_PS_NvMBlock_PDCReset_SetRamBlockStatus: start-on-event=SetRamBlockStatus, operation=PS_NvMBlock_PDCReset.SetRamBlockStatus
        OperationInvokedEvent_PS_NvMBlock_PDCReset_WriteBlock: start-on-event=WriteBlock, operation=PS_NvMBlock_PDCReset.WriteBlock
        OperationInvokedEvent_PS_NvMBlock_ANT_Calibration_CancelJobs: start-on-event=CancelJobs, operation=PS_NvMBlock_ANT_Calibration.CancelJobs
        OperationInvokedEvent_PS_NvMBlock_ANT_Calibration_EraseNvBlock: start-on-event=EraseNvBlock, operation=PS_NvMBlock_ANT_Calibration.EraseNvBlock
        OperationInvokedEvent_PS_NvMBlock_ANT_Calibration_GetErrorStatus: start-on-event=GetErrorStatus, operation=PS_NvMBlock_ANT_Calibration.GetErrorStatus
        OperationInvokedEvent_PS_NvMBlock_ANT_Calibration_InvalidateNvBlock: start-on-event=InvalidateNvBlock, operation=PS_NvMBlock_ANT_Calibration.InvalidateNvBlock
        OperationInvokedEvent_PS_NvMBlock_ANT_Calibration_ReadBlock: start-on-event=ReadBlock, operation=PS_NvMBlock_ANT_Calibration.ReadBlock
        OperationInvokedEvent_PS_NvMBlock_ANT_Calibration_RestoreBlockDefaults: start-on-event=RestoreBlockDefaults, operation=PS_NvMBlock_ANT_Calibration.RestoreBlockDefaults
        OperationInvokedEvent_PS_NvMBlock_ANT_Calibration_SetRamBlockStatus: start-on-event=SetRamBlockStatus, operation=PS_NvMBlock_ANT_Calibration.SetRamBlockStatus
        OperationInvokedEvent_PS_NvMBlock_ANT_Calibration_WriteBlock: start-on-event=WriteBlock, operation=PS_NvMBlock_ANT_Calibration.WriteBlock
        OperationInvokedEvent_PS_NvMBlock_B0BADisableCnt_CancelJobs: start-on-event=CancelJobs, operation=PS_NvMBlock_B0BADisableCnt.CancelJobs
        OperationInvokedEvent_PS_NvMBlock_B0BADisableCnt_EraseNvBlock: start-on-event=EraseNvBlock, operation=PS_NvMBlock_B0BADisableCnt.EraseNvBlock
        OperationInvokedEvent_PS_NvMBlock_B0BADisableCnt_GetErrorStatus: start-on-event=GetErrorStatus, operation=PS_NvMBlock_B0BADisableCnt.GetErrorStatus
        OperationInvokedEvent_PS_NvMBlock_B0BADisableCnt_InvalidateNvBlock: start-on-event=InvalidateNvBlock, operation=PS_NvMBlock_B0BADisableCnt.InvalidateNvBlock
        OperationInvokedEvent_PS_NvMBlock_B0BADisableCnt_ReadBlock: start-on-event=ReadBlock, operation=PS_NvMBlock_B0BADisableCnt.ReadBlock
        OperationInvokedEvent_PS_NvMBlock_B0BADisableCnt_RestoreBlockDefaults: start-on-event=RestoreBlockDefaults, operation=PS_NvMBlock_B0BADisableCnt.RestoreBlockDefaults
        OperationInvokedEvent_PS_NvMBlock_B0BADisableCnt_SetRamBlockStatus: start-on-event=SetRamBlockStatus, operation=PS_NvMBlock_B0BADisableCnt.SetRamBlockStatus
        OperationInvokedEvent_PS_NvMBlock_B0BADisableCnt_WriteBlock: start-on-event=WriteBlock, operation=PS_NvMBlock_B0BADisableCnt.WriteBlock
        OperationInvokedEvent_PS_NvMBlock_WctReproRequest_CancelJobs: start-on-event=CancelJobs, operation=PS_NvMBlock_WctReproRequest.CancelJobs
        OperationInvokedEvent_PS_NvMBlock_WctReproRequest_EraseNvBlock: start-on-event=EraseNvBlock, operation=PS_NvMBlock_WctReproRequest.EraseNvBlock
        OperationInvokedEvent_PS_NvMBlock_WctReproRequest_GetErrorStatus: start-on-event=GetErrorStatus, operation=PS_NvMBlock_WctReproRequest.GetErrorStatus
        OperationInvokedEvent_PS_NvMBlock_WctReproRequest_InvalidateNvBlock: start-on-event=InvalidateNvBlock, operation=PS_NvMBlock_WctReproRequest.InvalidateNvBlock
        OperationInvokedEvent_PS_NvMBlock_WctReproRequest_ReadBlock: start-on-event=ReadBlock, operation=PS_NvMBlock_WctReproRequest.ReadBlock
        OperationInvokedEvent_PS_NvMBlock_WctReproRequest_RestoreBlockDefaults: start-on-event=RestoreBlockDefaults, operation=PS_NvMBlock_WctReproRequest.RestoreBlockDefaults
        OperationInvokedEvent_PS_NvMBlock_WctReproRequest_SetRamBlockStatus: start-on-event=SetRamBlockStatus, operation=PS_NvMBlock_WctReproRequest.SetRamBlockStatus
        OperationInvokedEvent_PS_NvMBlock_WctReproRequest_WriteBlock: start-on-event=WriteBlock, operation=PS_NvMBlock_WctReproRequest.WriteBlock
        OperationInvokedEvent_PS_NvMBlock_Flag2_CancelJobs: start-on-event=CancelJobs, operation=PS_NvMBlock_Flag2.CancelJobs
        OperationInvokedEvent_PS_NvMBlock_Flag2_EraseNvBlock: start-on-event=EraseNvBlock, operation=PS_NvMBlock_Flag2.EraseNvBlock
        OperationInvokedEvent_PS_NvMBlock_Flag2_GetErrorStatus: start-on-event=GetErrorStatus, operation=PS_NvMBlock_Flag2.GetErrorStatus
        OperationInvokedEvent_PS_NvMBlock_Flag2_InvalidateNvBlock: start-on-event=InvalidateNvBlock, operation=PS_NvMBlock_Flag2.InvalidateNvBlock
        OperationInvokedEvent_PS_NvMBlock_Flag2_ReadBlock: start-on-event=ReadBlock, operation=PS_NvMBlock_Flag2.ReadBlock
        OperationInvokedEvent_PS_NvMBlock_Flag2_RestoreBlockDefaults: start-on-event=RestoreBlockDefaults, operation=PS_NvMBlock_Flag2.RestoreBlockDefaults
        OperationInvokedEvent_PS_NvMBlock_Flag2_SetRamBlockStatus: start-on-event=SetRamBlockStatus, operation=PS_NvMBlock_Flag2.SetRamBlockStatus
        OperationInvokedEvent_PS_NvMBlock_Flag2_WriteBlock: start-on-event=WriteBlock, operation=PS_NvMBlock_Flag2.WriteBlock
        OperationInvokedEvent_PS_NvMBlock_Flag3_CancelJobs: start-on-event=CancelJobs, operation=PS_NvMBlock_Flag3.CancelJobs
        OperationInvokedEvent_PS_NvMBlock_Flag3_EraseNvBlock: start-on-event=EraseNvBlock, operation=PS_NvMBlock_Flag3.EraseNvBlock
        OperationInvokedEvent_PS_NvMBlock_Flag3_GetErrorStatus: start-on-event=GetErrorStatus, operation=PS_NvMBlock_Flag3.GetErrorStatus
        OperationInvokedEvent_PS_NvMBlock_Flag3_InvalidateNvBlock: start-on-event=InvalidateNvBlock, operation=PS_NvMBlock_Flag3.InvalidateNvBlock
        OperationInvokedEvent_PS_NvMBlock_Flag3_ReadBlock: start-on-event=ReadBlock, operation=PS_NvMBlock_Flag3.ReadBlock
        OperationInvokedEvent_PS_NvMBlock_Flag3_RestoreBlockDefaults: start-on-event=RestoreBlockDefaults, operation=PS_NvMBlock_Flag3.RestoreBlockDefaults
        OperationInvokedEvent_PS_NvMBlock_Flag3_SetRamBlockStatus: start-on-event=SetRamBlockStatus, operation=PS_NvMBlock_Flag3.SetRamBlockStatus
        OperationInvokedEvent_PS_NvMBlock_Flag3_WriteBlock: start-on-event=WriteBlock, operation=PS_NvMBlock_Flag3.WriteBlock
        OperationInvokedEvent_PS_NvMBlock_Flag4_CancelJobs: start-on-event=CancelJobs, operation=PS_NvMBlock_Flag4.CancelJobs
        OperationInvokedEvent_PS_NvMBlock_Flag4_EraseNvBlock: start-on-event=EraseNvBlock, operation=PS_NvMBlock_Flag4.EraseNvBlock
        OperationInvokedEvent_PS_NvMBlock_Flag4_GetErrorStatus: start-on-event=GetErrorStatus, operation=PS_NvMBlock_Flag4.GetErrorStatus
        OperationInvokedEvent_PS_NvMBlock_Flag4_InvalidateNvBlock: start-on-event=InvalidateNvBlock, operation=PS_NvMBlock_Flag4.InvalidateNvBlock
        OperationInvokedEvent_PS_NvMBlock_Flag4_ReadBlock: start-on-event=ReadBlock, operation=PS_NvMBlock_Flag4.ReadBlock
        OperationInvokedEvent_PS_NvMBlock_Flag4_RestoreBlockDefaults: start-on-event=RestoreBlockDefaults, operation=PS_NvMBlock_Flag4.RestoreBlockDefaults
        OperationInvokedEvent_PS_NvMBlock_Flag4_SetRamBlockStatus: start-on-event=SetRamBlockStatus, operation=PS_NvMBlock_Flag4.SetRamBlockStatus
        OperationInvokedEvent_PS_NvMBlock_Flag4_WriteBlock: start-on-event=WriteBlock, operation=PS_NvMBlock_Flag4.WriteBlock
        OperationInvokedEvent_PS_NvMBlock_Flag5_CancelJobs: start-on-event=CancelJobs, operation=PS_NvMBlock_Flag5.CancelJobs
        OperationInvokedEvent_PS_NvMBlock_Flag5_EraseNvBlock: start-on-event=EraseNvBlock, operation=PS_NvMBlock_Flag5.EraseNvBlock
        OperationInvokedEvent_PS_NvMBlock_Flag5_GetErrorStatus: start-on-event=GetErrorStatus, operation=PS_NvMBlock_Flag5.GetErrorStatus
        OperationInvokedEvent_PS_NvMBlock_Flag5_InvalidateNvBlock: start-on-event=InvalidateNvBlock, operation=PS_NvMBlock_Flag5.InvalidateNvBlock
        OperationInvokedEvent_PS_NvMBlock_Flag5_ReadBlock: start-on-event=ReadBlock, operation=PS_NvMBlock_Flag5.ReadBlock
        OperationInvokedEvent_PS_NvMBlock_Flag5_RestoreBlockDefaults: start-on-event=RestoreBlockDefaults, operation=PS_NvMBlock_Flag5.RestoreBlockDefaults
        OperationInvokedEvent_PS_NvMBlock_Flag5_SetRamBlockStatus: start-on-event=SetRamBlockStatus, operation=PS_NvMBlock_Flag5.SetRamBlockStatus
        OperationInvokedEvent_PS_NvMBlock_Flag5_WriteBlock: start-on-event=WriteBlock, operation=PS_NvMBlock_Flag5.WriteBlock
        OperationInvokedEvent_PS_NvMBlock_Flag6_CancelJobs: start-on-event=CancelJobs, operation=PS_NvMBlock_Flag6.CancelJobs
        OperationInvokedEvent_PS_NvMBlock_Flag6_EraseNvBlock: start-on-event=EraseNvBlock, operation=PS_NvMBlock_Flag6.EraseNvBlock
        OperationInvokedEvent_PS_NvMBlock_Flag6_GetErrorStatus: start-on-event=GetErrorStatus, operation=PS_NvMBlock_Flag6.GetErrorStatus
        OperationInvokedEvent_PS_NvMBlock_Flag6_InvalidateNvBlock: start-on-event=InvalidateNvBlock, operation=PS_NvMBlock_Flag6.InvalidateNvBlock
        OperationInvokedEvent_PS_NvMBlock_Flag6_ReadBlock: start-on-event=ReadBlock, operation=PS_NvMBlock_Flag6.ReadBlock
        OperationInvokedEvent_PS_NvMBlock_Flag6_RestoreBlockDefaults: start-on-event=RestoreBlockDefaults, operation=PS_NvMBlock_Flag6.RestoreBlockDefaults
        OperationInvokedEvent_PS_NvMBlock_Flag6_SetRamBlockStatus: start-on-event=SetRamBlockStatus, operation=PS_NvMBlock_Flag6.SetRamBlockStatus
        OperationInvokedEvent_PS_NvMBlock_Flag6_WriteBlock: start-on-event=WriteBlock, operation=PS_NvMBlock_Flag6.WriteBlock
        OperationInvokedEvent_PS_NvMBlock_ECU_Info_CancelJobs: start-on-event=CancelJobs, operation=PS_NvMBlock_ECU_Info.CancelJobs
        OperationInvokedEvent_PS_NvMBlock_ECU_Info_EraseNvBlock: start-on-event=EraseNvBlock, operation=PS_NvMBlock_ECU_Info.EraseNvBlock
        OperationInvokedEvent_PS_NvMBlock_ECU_Info_GetErrorStatus: start-on-event=GetErrorStatus, operation=PS_NvMBlock_ECU_Info.GetErrorStatus
        OperationInvokedEvent_PS_NvMBlock_ECU_Info_InvalidateNvBlock: start-on-event=InvalidateNvBlock, operation=PS_NvMBlock_ECU_Info.InvalidateNvBlock
        OperationInvokedEvent_PS_NvMBlock_ECU_Info_ReadBlock: start-on-event=ReadBlock, operation=PS_NvMBlock_ECU_Info.ReadBlock
        OperationInvokedEvent_PS_NvMBlock_ECU_Info_RestoreBlockDefaults: start-on-event=RestoreBlockDefaults, operation=PS_NvMBlock_ECU_Info.RestoreBlockDefaults
        OperationInvokedEvent_PS_NvMBlock_ECU_Info_SetRamBlockStatus: start-on-event=SetRamBlockStatus, operation=PS_NvMBlock_ECU_Info.SetRamBlockStatus
        OperationInvokedEvent_PS_NvMBlock_ECU_Info_WriteBlock: start-on-event=WriteBlock, operation=PS_NvMBlock_ECU_Info.WriteBlock
        OperationInvokedEvent_PS_NvMBlock_SerialNum_CancelJobs: start-on-event=CancelJobs, operation=PS_NvMBlock_SerialNum.CancelJobs
        OperationInvokedEvent_PS_NvMBlock_SerialNum_EraseNvBlock: start-on-event=EraseNvBlock, operation=PS_NvMBlock_SerialNum.EraseNvBlock
        OperationInvokedEvent_PS_NvMBlock_SerialNum_GetErrorStatus: start-on-event=GetErrorStatus, operation=PS_NvMBlock_SerialNum.GetErrorStatus
        OperationInvokedEvent_PS_NvMBlock_SerialNum_InvalidateNvBlock: start-on-event=InvalidateNvBlock, operation=PS_NvMBlock_SerialNum.InvalidateNvBlock
        OperationInvokedEvent_PS_NvMBlock_SerialNum_ReadBlock: start-on-event=ReadBlock, operation=PS_NvMBlock_SerialNum.ReadBlock
        OperationInvokedEvent_PS_NvMBlock_SerialNum_RestoreBlockDefaults: start-on-event=RestoreBlockDefaults, operation=PS_NvMBlock_SerialNum.RestoreBlockDefaults
        OperationInvokedEvent_PS_NvMBlock_SerialNum_SetRamBlockStatus: start-on-event=SetRamBlockStatus, operation=PS_NvMBlock_SerialNum.SetRamBlockStatus
        OperationInvokedEvent_PS_NvMBlock_SerialNum_WriteBlock: start-on-event=WriteBlock, operation=PS_NvMBlock_SerialNum.WriteBlock
        OperationInvokedEvent_PS_NvMBlock_QRCode_CancelJobs: start-on-event=CancelJobs, operation=PS_NvMBlock_QRCode.CancelJobs
        OperationInvokedEvent_PS_NvMBlock_QRCode_EraseNvBlock: start-on-event=EraseNvBlock, operation=PS_NvMBlock_QRCode.EraseNvBlock
        OperationInvokedEvent_PS_NvMBlock_QRCode_GetErrorStatus: start-on-event=GetErrorStatus, operation=PS_NvMBlock_QRCode.GetErrorStatus
        OperationInvokedEvent_PS_NvMBlock_QRCode_InvalidateNvBlock: start-on-event=InvalidateNvBlock, operation=PS_NvMBlock_QRCode.InvalidateNvBlock
        OperationInvokedEvent_PS_NvMBlock_QRCode_ReadBlock: start-on-event=ReadBlock, operation=PS_NvMBlock_QRCode.ReadBlock
        OperationInvokedEvent_PS_NvMBlock_QRCode_RestoreBlockDefaults: start-on-event=RestoreBlockDefaults, operation=PS_NvMBlock_QRCode.RestoreBlockDefaults
        OperationInvokedEvent_PS_NvMBlock_QRCode_SetRamBlockStatus: start-on-event=SetRamBlockStatus, operation=PS_NvMBlock_QRCode.SetRamBlockStatus
        OperationInvokedEvent_PS_NvMBlock_QRCode_WriteBlock: start-on-event=WriteBlock, operation=PS_NvMBlock_QRCode.WriteBlock
        OperationInvokedEvent_PS_NvMBlock_Array1_CancelJobs: start-on-event=CancelJobs, operation=PS_NvMBlock_Array1.CancelJobs
        OperationInvokedEvent_PS_NvMBlock_Array1_EraseNvBlock: start-on-event=EraseNvBlock, operation=PS_NvMBlock_Array1.EraseNvBlock
        OperationInvokedEvent_PS_NvMBlock_Array1_GetErrorStatus: start-on-event=GetErrorStatus, operation=PS_NvMBlock_Array1.GetErrorStatus
        OperationInvokedEvent_PS_NvMBlock_Array1_InvalidateNvBlock: start-on-event=InvalidateNvBlock, operation=PS_NvMBlock_Array1.InvalidateNvBlock
        OperationInvokedEvent_PS_NvMBlock_Array1_ReadBlock: start-on-event=ReadBlock, operation=PS_NvMBlock_Array1.ReadBlock
        OperationInvokedEvent_PS_NvMBlock_Array1_RestoreBlockDefaults: start-on-event=RestoreBlockDefaults, operation=PS_NvMBlock_Array1.RestoreBlockDefaults
        OperationInvokedEvent_PS_NvMBlock_Array1_SetRamBlockStatus: start-on-event=SetRamBlockStatus, operation=PS_NvMBlock_Array1.SetRamBlockStatus
        OperationInvokedEvent_PS_NvMBlock_Array1_WriteBlock: start-on-event=WriteBlock, operation=PS_NvMBlock_Array1.WriteBlock
        OperationInvokedEvent_PS_NvMBlock_Array2_CancelJobs: start-on-event=CancelJobs, operation=PS_NvMBlock_Array2.CancelJobs
        OperationInvokedEvent_PS_NvMBlock_Array2_EraseNvBlock: start-on-event=EraseNvBlock, operation=PS_NvMBlock_Array2.EraseNvBlock
        OperationInvokedEvent_PS_NvMBlock_Array2_GetErrorStatus: start-on-event=GetErrorStatus, operation=PS_NvMBlock_Array2.GetErrorStatus
        OperationInvokedEvent_PS_NvMBlock_Array2_InvalidateNvBlock: start-on-event=InvalidateNvBlock, operation=PS_NvMBlock_Array2.InvalidateNvBlock
        OperationInvokedEvent_PS_NvMBlock_Array2_ReadBlock: start-on-event=ReadBlock, operation=PS_NvMBlock_Array2.ReadBlock
        OperationInvokedEvent_PS_NvMBlock_Array2_RestoreBlockDefaults: start-on-event=RestoreBlockDefaults, operation=PS_NvMBlock_Array2.RestoreBlockDefaults
        OperationInvokedEvent_PS_NvMBlock_Array2_SetRamBlockStatus: start-on-event=SetRamBlockStatus, operation=PS_NvMBlock_Array2.SetRamBlockStatus
        OperationInvokedEvent_PS_NvMBlock_Array2_WriteBlock: start-on-event=WriteBlock, operation=PS_NvMBlock_Array2.WriteBlock
        OperationInvokedEvent_PS_NvMBlock_Array3_CancelJobs: start-on-event=CancelJobs, operation=PS_NvMBlock_Array3.CancelJobs
        OperationInvokedEvent_PS_NvMBlock_Array3_EraseNvBlock: start-on-event=EraseNvBlock, operation=PS_NvMBlock_Array3.EraseNvBlock
        OperationInvokedEvent_PS_NvMBlock_Array3_GetErrorStatus: start-on-event=GetErrorStatus, operation=PS_NvMBlock_Array3.GetErrorStatus
        OperationInvokedEvent_PS_NvMBlock_Array3_InvalidateNvBlock: start-on-event=InvalidateNvBlock, operation=PS_NvMBlock_Array3.InvalidateNvBlock
        OperationInvokedEvent_PS_NvMBlock_Array3_ReadBlock: start-on-event=ReadBlock, operation=PS_NvMBlock_Array3.ReadBlock
        OperationInvokedEvent_PS_NvMBlock_Array3_RestoreBlockDefaults: start-on-event=RestoreBlockDefaults, operation=PS_NvMBlock_Array3.RestoreBlockDefaults
        OperationInvokedEvent_PS_NvMBlock_Array3_SetRamBlockStatus: start-on-event=SetRamBlockStatus, operation=PS_NvMBlock_Array3.SetRamBlockStatus
        OperationInvokedEvent_PS_NvMBlock_Array3_WriteBlock: start-on-event=WriteBlock, operation=PS_NvMBlock_Array3.WriteBlock
        OperationInvokedEvent_PS_NvMBlock_DataLog_CancelJobs: start-on-event=CancelJobs, operation=PS_NvMBlock_DataLog.CancelJobs
        OperationInvokedEvent_PS_NvMBlock_DataLog_EraseNvBlock: start-on-event=EraseNvBlock, operation=PS_NvMBlock_DataLog.EraseNvBlock
        OperationInvokedEvent_PS_NvMBlock_DataLog_GetErrorStatus: start-on-event=GetErrorStatus, operation=PS_NvMBlock_DataLog.GetErrorStatus
        OperationInvokedEvent_PS_NvMBlock_DataLog_InvalidateNvBlock: start-on-event=InvalidateNvBlock, operation=PS_NvMBlock_DataLog.InvalidateNvBlock
        OperationInvokedEvent_PS_NvMBlock_DataLog_ReadBlock: start-on-event=ReadBlock, operation=PS_NvMBlock_DataLog.ReadBlock
        OperationInvokedEvent_PS_NvMBlock_DataLog_RestoreBlockDefaults: start-on-event=RestoreBlockDefaults, operation=PS_NvMBlock_DataLog.RestoreBlockDefaults
        OperationInvokedEvent_PS_NvMBlock_DataLog_SetRamBlockStatus: start-on-event=SetRamBlockStatus, operation=PS_NvMBlock_DataLog.SetRamBlockStatus
        OperationInvokedEvent_PS_NvMBlock_DataLog_WriteBlock: start-on-event=WriteBlock, operation=PS_NvMBlock_DataLog.WriteBlock
        OperationInvokedEvent_PS_NvMBlock_NmlLog_CancelJobs: start-on-event=CancelJobs, operation=PS_NvMBlock_NmlLog.CancelJobs
        OperationInvokedEvent_PS_NvMBlock_NmlLog_EraseNvBlock: start-on-event=EraseNvBlock, operation=PS_NvMBlock_NmlLog.EraseNvBlock
        OperationInvokedEvent_PS_NvMBlock_NmlLog_GetErrorStatus: start-on-event=GetErrorStatus, operation=PS_NvMBlock_NmlLog.GetErrorStatus
        OperationInvokedEvent_PS_NvMBlock_NmlLog_InvalidateNvBlock: start-on-event=InvalidateNvBlock, operation=PS_NvMBlock_NmlLog.InvalidateNvBlock
        OperationInvokedEvent_PS_NvMBlock_NmlLog_ReadBlock: start-on-event=ReadBlock, operation=PS_NvMBlock_NmlLog.ReadBlock
        OperationInvokedEvent_PS_NvMBlock_NmlLog_RestoreBlockDefaults: start-on-event=RestoreBlockDefaults, operation=PS_NvMBlock_NmlLog.RestoreBlockDefaults
        OperationInvokedEvent_PS_NvMBlock_NmlLog_SetRamBlockStatus: start-on-event=SetRamBlockStatus, operation=PS_NvMBlock_NmlLog.SetRamBlockStatus
        OperationInvokedEvent_PS_NvMBlock_NmlLog_WriteBlock: start-on-event=WriteBlock, operation=PS_NvMBlock_NmlLog.WriteBlock
      port-api-options:
        {enable-take-address=false, indirect-api=false, port-defined-argument-value{value=Block1:1, value-type=NvM_BlockIdType}, port=PS_NvMBlock_ConfigID}
        {enable-take-address=false, indirect-api=false, port-defined-argument-value{value=Block9:9, value-type=NvM_BlockIdType}, port=PS_NvMBlock_IntTst_TestBlock1}
        {enable-take-address=false, indirect-api=false, port-defined-argument-value{value=Block10:10, value-type=NvM_BlockIdType}, port=PS_NvMBlock_IntTst_TestBlock2}
        {enable-take-address=false, indirect-api=false, port-defined-argument-value{value=Block11:11, value-type=NvM_BlockIdType}, port=PS_NvMBlock_IntTst_TestBlock3}
        {enable-take-address=false, indirect-api=false, port-defined-argument-value{value=Block12:12, value-type=NvM_BlockIdType}, port=PS_NvMBlock_ProfileGuestWPCUSM0}
        {enable-take-address=false, indirect-api=false, port-defined-argument-value{value=Block13:13, value-type=NvM_BlockIdType}, port=PS_NvMBlock_ProfileOneWPCUSM0}
        {enable-take-address=false, indirect-api=false, port-defined-argument-value{value=Block14:14, value-type=NvM_BlockIdType}, port=PS_NvMBlock_ProfileTwoWPCUSM0}
        {enable-take-address=false, indirect-api=false, port-defined-argument-value{value=Block15:15, value-type=NvM_BlockIdType}, port=PS_NvMBlock_ProfileThreeWPCUSM0}
        {enable-take-address=false, indirect-api=false, port-defined-argument-value{value=Block16:16, value-type=NvM_BlockIdType}, port=PS_NvMBlock_RWPCUSM0}
        {enable-take-address=false, indirect-api=false, port-defined-argument-value{value=Block17:17, value-type=NvM_BlockIdType}, port=PS_NvMBlock_ProfileGuestWPCUSM1}
        {enable-take-address=false, indirect-api=false, port-defined-argument-value{value=Block18:18, value-type=NvM_BlockIdType}, port=PS_NvMBlock_ProfileOneWPCUSM1}
        {enable-take-address=false, indirect-api=false, port-defined-argument-value{value=Block19:19, value-type=NvM_BlockIdType}, port=PS_NvMBlock_ProfileTwoWPCUSM1}
        {enable-take-address=false, indirect-api=false, port-defined-argument-value{value=Block20:20, value-type=NvM_BlockIdType}, port=PS_NvMBlock_ProfileThreeWPCUSM1}
        {enable-take-address=false, indirect-api=false, port-defined-argument-value{value=Block21:21, value-type=NvM_BlockIdType}, port=PS_NvMBlock_RWPCUSM1}
        {enable-take-address=false, indirect-api=false, port-defined-argument-value{value=Block22:22, value-type=NvM_BlockIdType}, port=PS_NvMBlock_AutoBrightSta}
        {enable-take-address=false, indirect-api=false, port-defined-argument-value{value=Block23:23, value-type=NvM_BlockIdType}, port=PS_NvMBlock_PDCReset}
        {enable-take-address=false, indirect-api=false, port-defined-argument-value{value=Block24:24, value-type=NvM_BlockIdType}, port=PS_NvMBlock_ANT_Calibration}
        {enable-take-address=false, indirect-api=false, port-defined-argument-value{value=Block25:25, value-type=NvM_BlockIdType}, port=PS_NvMBlock_B0BADisableCnt}
        {enable-take-address=false, indirect-api=false, port-defined-argument-value{value=Block26:26, value-type=NvM_BlockIdType}, port=PS_NvMBlock_WctReproRequest}
        {enable-take-address=false, indirect-api=false, port-defined-argument-value{value=Block27:27, value-type=NvM_BlockIdType}, port=PS_NvMBlock_Flag2}
        {enable-take-address=false, indirect-api=false, port-defined-argument-value{value=Block28:28, value-type=NvM_BlockIdType}, port=PS_NvMBlock_Flag3}
        {enable-take-address=false, indirect-api=false, port-defined-argument-value{value=Block29:29, value-type=NvM_BlockIdType}, port=PS_NvMBlock_Flag4}
        {enable-take-address=false, indirect-api=false, port-defined-argument-value{value=Block30:30, value-type=NvM_BlockIdType}, port=PS_NvMBlock_Flag5}
        {enable-take-address=false, indirect-api=false, port-defined-argument-value{value=Block31:31, value-type=NvM_BlockIdType}, port=PS_NvMBlock_Flag6}
        {enable-take-address=false, indirect-api=false, port-defined-argument-value{value=Block32:32, value-type=NvM_BlockIdType}, port=PS_NvMBlock_ECU_Info}
        {enable-take-address=false, indirect-api=false, port-defined-argument-value{value=Block33:33, value-type=NvM_BlockIdType}, port=PS_NvMBlock_SerialNum}
        {enable-take-address=false, indirect-api=false, port-defined-argument-value{value=Block34:34, value-type=NvM_BlockIdType}, port=PS_NvMBlock_QRCode}
        {enable-take-address=false, indirect-api=false, port-defined-argument-value{value=Block35:35, value-type=NvM_BlockIdType}, port=PS_NvMBlock_Array1}
        {enable-take-address=false, indirect-api=false, port-defined-argument-value{value=Block36:36, value-type=NvM_BlockIdType}, port=PS_NvMBlock_Array2}
        {enable-take-address=false, indirect-api=false, port-defined-argument-value{value=Block37:37, value-type=NvM_BlockIdType}, port=PS_NvMBlock_Array3}
        {enable-take-address=false, indirect-api=false, port-defined-argument-value{value=Block38:38, value-type=NvM_BlockIdType}, port=PS_NvMBlock_DataLog}
        {enable-take-address=false, indirect-api=false, port-defined-argument-value{value=Block39:39, value-type=NvM_BlockIdType}, port=PS_NvMBlock_NmlLog}
      9 x runnable:
        CancelJobs: runnable-entity-argument=symbol=BlockId, can-be-invoked-concurrently=true, symbol=NvM_CancelJobs
        EraseNvBlock: runnable-entity-argument=symbol=BlockId, can-be-invoked-concurrently=true, symbol=NvM_EraseNvBlock
        GetErrorStatus: arguments=[symbol=BlockId, symbol=RequestResultPtr], can-be-invoked-concurrently=true, symbol=NvM_GetErrorStatus
        InvalidateNvBlock: runnable-entity-argument=symbol=BlockId, can-be-invoked-concurrently=true, symbol=NvM_InvalidateNvBlock
        ReadBlock: arguments=[symbol=BlockId, symbol=NvM_DstPtr], can-be-invoked-concurrently=true, symbol=NvM_ReadBlock
        RestoreBlockDefaults: arguments=[symbol=BlockId, symbol=NvM_DstPtr], can-be-invoked-concurrently=true, symbol=NvM_RestoreBlockDefaults
        SetRamBlockStatus: runnable-entity-argument=symbol=BlockId, can-be-invoked-concurrently=true, symbol=NvM_SetRamBlockStatus
        WriteBlock: arguments=[symbol=BlockId, symbol=NvM_SrcPtr], can-be-invoked-concurrently=true, symbol=NvM_WriteBlock
        MainFunction: symbol=NvM_MainFunction
          sync call SynchronousServerCallPoint_JF_NvMBlock_IntTst_TestBlock{1..3}: operation=PNJF_NvMBlock_IntTst_TestBlock{1..3}.JobFinished, timeout=0.0
  swc implementation SwcImplementation_NvM: programming-language=C, sw-version=1.7.0, swc-bsw-mapping=SwcBswMapping_NvM, vendor-id=59, behavior=IB_NvM
    code-descriptors:
      code Code: artifact-descriptors=autosar-engineering-object={short-label=NvM, category=SWOBJ}
    resource consumption ResourceConsumption
  swc bsw mapping SwcBswMapping_NvM: bsw-behavior=BswInternalBehavior_NvM, swc-bsw-runnable-mapping{bsw-entity=BswSE_NvM_MainFunction, swc-runnable=MainFunction}, swc-behavior=IB_NvM
